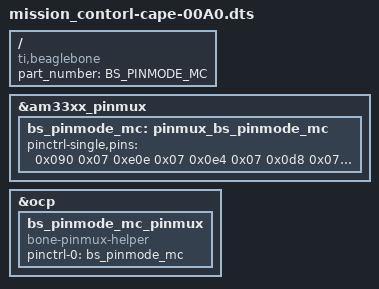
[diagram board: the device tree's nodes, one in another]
/*
 * This is an overlay for the beagle bone black in MISSION CONTROL.
 * The purpose is to set up the BBB to use the gpio of P8 and P9 to send the ARM and IGNITE signals.
 * Author: Patricio Castillo Calderon
 */

/dts-v1/;
/plugin/;

/{
    compatible = "ti,beaglebone", "ti,beaglebone-black";
    part_number = "BS_PINMODE_MC";

    fragment@0 {
        target = <&am33xx_pinmux>;
        __overlay__ {
            bs_pinmode_mc: pinmux_bs_pinmode_mc {
                pinctrl-single,pins = <

			/* LEDS*/

			0x090 0x07 /* P8_7 */
                        0xe0e 0x07 /* P8_27 */
                        0x0e4 0x07 /* P8_29 */
                        0x0d8 0x07 /* P8_31 */
                        0x0d4 0x07 /* P8_33 */
                        0x0d0 0x07 /* P8_35 */
			/*BUTTONS*/

                        0x070 0x27 /* P9_11 */
                        0x074 0x27 /* P9_13 */
                        0x040 0x27 /* P9_15 */
                        0x154 0x27 /* P9_21 */
                        0x044 0x27 /* P9_23 */
                        0x1a4 0x27 /* P9_27 */
                >;
            };
        };
    };

    fragment@1 {
        target = <&ocp>;
        __overlay__ {
            bs_pinmode_mc_pinmux {
                compatible = "bone-pinmux-helper";
                status = "okay";
                pinctrl-names = "default";
                pinctrl-0 = <&bs_pinmode_mc>;
            };
        };
    };
};

